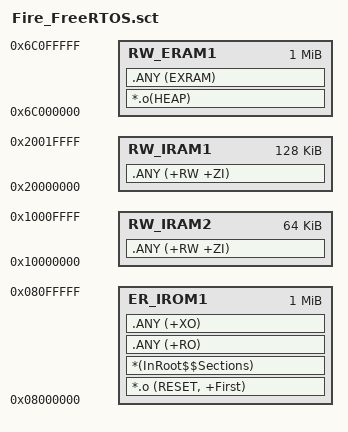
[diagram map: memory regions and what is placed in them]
; *************************************************************
; *** Scatter-Loading Description File generated by uVision ***
; *************************************************************

LR_IROM1 0x08000000 0x00100000  {    ; load region size_region
  ER_IROM1 0x08000000 0x00100000  {  ; load address = execution address
   *.o (RESET, +First)
   *(InRoot$$Sections)
   .ANY (+RO)
   .ANY (+XO)
  }
  RW_IRAM1 0x20000000 0x00020000  {  ; RW data
   .ANY (+RW +ZI)
  }
  RW_IRAM2 0x10000000 0x00010000  {
   .ANY (+RW +ZI)
  }
;  RW_IRAM1 0x20000000 0x00030000  {  ; 内部SRAM 
;  .ANY (+RW +ZI)      ;其余的RW/ZI-data都分配到这里
;  }
   
  RW_ERAM1 0x6C000000 0x00100000 {  ; 外部SDRAM
  *.o(HEAP)            ;选择堆区
  .ANY (EXRAM)       ;选择EXRAM节区
  }
  
}

